# LCM32F039 register map
File version: 1.0
CPU: CM0 r1p0, little endian, MPU, no FPU, 3 interrupt priority bits
Registers are 32-bit, read-write, reset 0x0 unless marked. A register's access mark holds for its fields unless they carry their own. Offsets are from the block's base; [hi:lo] are bit positions; {n}, {i} and the like mark numbered series.

## SPI0 — ARM PrimeCell SSP (PL022)
Base 0x40018000
Same registers: SPI2 0x40006000
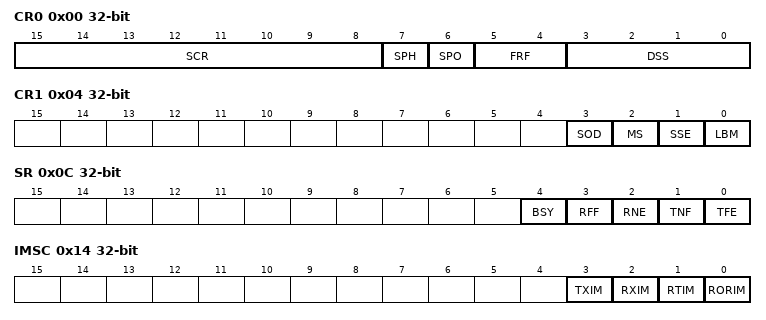
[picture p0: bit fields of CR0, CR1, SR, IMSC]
0x00 CR0 — Control register 0
  [15:8] SCR — Serial clock rate.
  [7] SPH — SSPCLKOUT phase, applicable to Motorola SPI frame format only.
  [6] SPO — SSPCLKOUT polarity, applicable to Motorola SPI frame
  [5:4] FRF — Frame format
  [3:0] DSS — Data Size Select
0x04 CR1 — Control register 1
  [3] SOD — Slave-mode output disable.
  [2] MS — Master or slave mode select
  [1] SSE — Synchronous serial port enable
  [0] LBM — Loop back mode.
0x08 DR — Data register
  [15:0] DATA — Transmit/Receive FIFO
0x0C SR ro — Status register
  [4] BSY — PrimeCell SSP busy flag
  [3] RFF — Receive FIFO full
  [2] RNE — Receive FIFO not empty
  [1] TNF — Transmit FIFO not full
  [0] TFE — Transmit FIFO empty
0x10 CPSR ro — Clock prescale register.
  [7:0] CPSDVSR — Clock prescale divisor.
0x14 IMSC — Interrupt mask set or clear register
  [3] TXIM — Transmit FIFO interrupt mask
  [2] RXIM — Receive FIFO interrupt mask
  [1] RTIM — Receive timeout interrupt mask
  [0] RORIM — Receive overrun interrupt mask
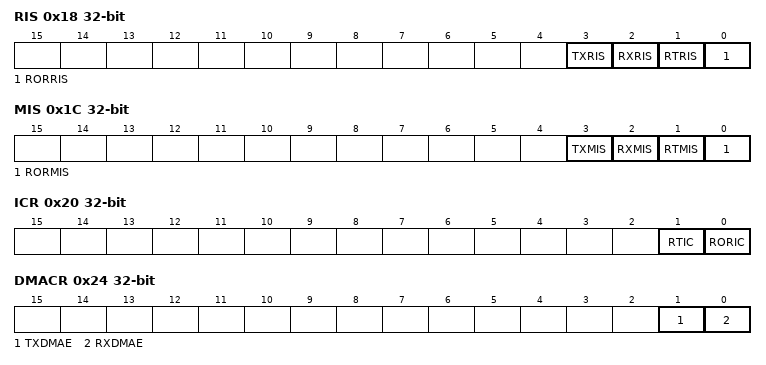
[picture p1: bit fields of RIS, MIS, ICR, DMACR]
0x18 RIS ro — Raw interrupt status register
  [3] TXRIS — Gives the raw interrupt state, prior to masking, of the SSPTXINTR interrupt
  [2] RXRIS — Gives the raw interrupt state, prior to masking, of the SSPRXINTR interrupt
  [1] RTRIS — Gives the raw interrupt state, prior to masking, of the SSPRTINTR interrupt
  [0] RORRIS — Gives the raw interrupt state, prior to masking, of the SSPRORINTR interrupt
0x1C MIS ro — Masked interrupt status register
  [3] TXMIS — Gives the transmit FIFO masked interrupt state, after masking, of the SSPTXINTR interrupt
  [2] RXMIS — Gives the receive FIFO masked interrupt state, after masking, of the SSPRXINTR interrupt
  [1] RTMIS — Gives the receive timeout masked interrupt state, after masking, of the SSPRTINTR interrupt
  [0] RORMIS — Gives the receive over run masked interrupt status, after masking, of the SSPRORINTR interrupt
0x20 ICR wo — Interrupt clear register
  [1] RTIC — Clears the SSPRTINTR interrupt
  [0] RORIC — Clears the SSPRORINTR interrupt
0x24 DMACR — DMA control register
  [1] TXDMAE — Transmit DMA Enable. If this bit is set to 1, DMA for the transmit FIFO is enabled.
  [0] RXDMAE — Receive DMA Enable. If this bit is set to 1, DMA for the receive FIFO is enabled.

## LCD — liquid crystal display
Base 0x40008000
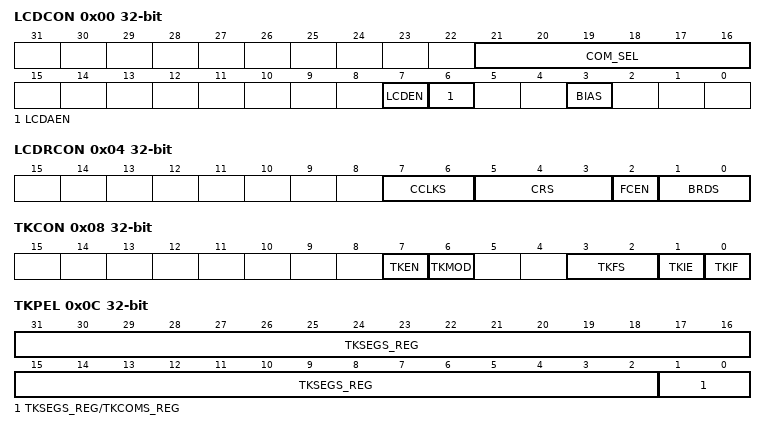
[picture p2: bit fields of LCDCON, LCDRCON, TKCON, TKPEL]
0x00 LCDCON — Flash access control register
  [21:16] COM_SEL — Enable the selection bit on the COM end
  [7] LCDEN — Enable position of the LCD module
  [6] LCDAEN — Simulation test output enable bit
  [3] BIAS — Bias level selector bit
0x04 LCDRCON — LCD resistor drive control register
  [7:6] CCLKS — Charging time selection bit
  [5:3] CRS — Contrast selector bit
  [2] FCEN — Quick charging enable.
  [1:0] BRDS — Bias resistor selection bit
0x08 TKCON — LCD flicker control register
  [7] TKEN — Blinking always enable
  [6] TKMOD — Blinking mode control bit
  [3:2] TKFS — Flicker frequency selection bit
  [1] TKIE — Blinking interrupt enable position
  [0] TKIF — Blinking interrupt flag bit
0x0C TKPEL — Blinking enable signal low level control register
  [31:2] TKSEGS_REG — Enable SEG pin
  [1:0] TKSEGS_REG/TKCOMS_REG — Com/SEG output enable bit
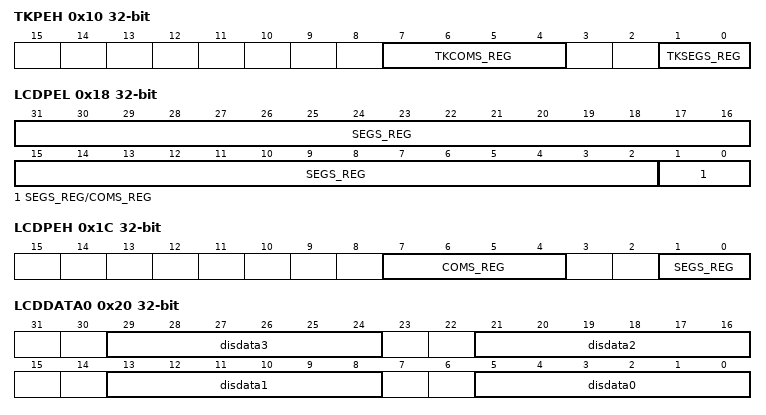
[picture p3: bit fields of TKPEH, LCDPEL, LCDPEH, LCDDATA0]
0x10 TKPEH — LCD flicker enable signal high control register
  [7:4] TKCOMS_REG — Blinking always enable
  [1:0] TKSEGS_REG — Blinking enable
0x14 LCDSCDIV — LCD scan clock source frequency division control register
  [7:0] LCDSCDIV — LCD scanning clock source frequency division control bit
0x18 LCDPEL — LCD output enable signal low level control register
  [31:2] SEGS_REG — Enable SEG pin
  [1:0] SEGS_REG/COMS_REG — Com/SEG output enable bit
0x1C LCDPEH — LCD output enable signal high control register
  [7:4] COMS_REG — Enable COM pin
  [1:0] SEGS_REG — Enable SEG pin
0x20 LCDDATA0 — SEG output data register 0
  [8n+5:8n] disdata{n} (n=0..3) — The SEG{n} pin outputs COM signals
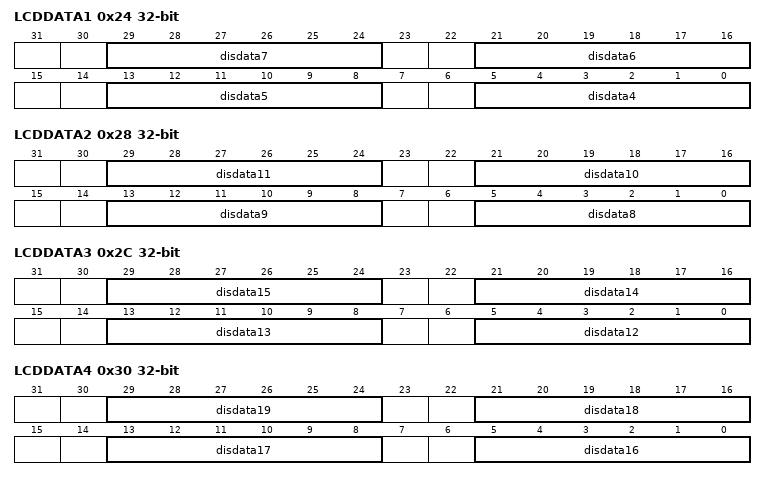
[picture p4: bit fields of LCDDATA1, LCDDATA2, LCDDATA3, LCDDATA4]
0x24 LCDDATA1 — SEG output data register 1
  [8n-27:8n-32] disdata{n} (n=4..7) — The SEG{n} pin outputs COM signals
0x28 LCDDATA2 — SEG output data register 2
  [8n-59:8n-64] disdata{n} (n=8..11) — The SEG{n} pin outputs COM signals
0x2C LCDDATA3 — SEG output data register 3
  [8n-91:8n-96] disdata{n} (n=12..15) — The SEG{n} pin outputs COM signals
0x30 LCDDATA4 — SEG output data register 4
  [8n-123:8n-128] disdata{n} (n=16..19) — The SEG{n} pin outputs COM signals
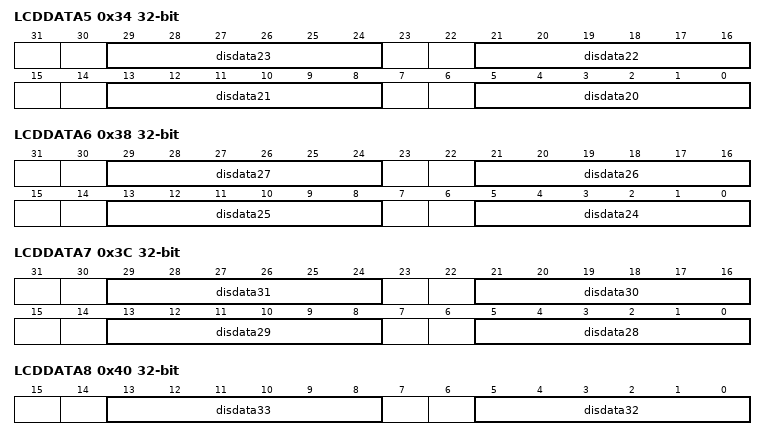
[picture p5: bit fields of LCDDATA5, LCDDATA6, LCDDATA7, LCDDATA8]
0x34 LCDDATA5 — SEG output data register 5
  [8n-155:8n-160] disdata{n} (n=20..23) — The SEG{n} pin outputs COM signals
0x38 LCDDATA6 — SEG output data register 6
  [8n-187:8n-192] disdata{n} (n=24..27) — The SEG{n} pin outputs COM signals
0x3C LCDDATA7 — SEG output data register 7
  [8n-219:8n-224] disdata{n} (n=28..31) — The SEG{n} pin outputs COM signals
0x40 LCDDATA8 — SEG output data register 8
  [13:8] disdata33 — The SEG33 pin outputs COM signals
  [5:0] disdata32 — The SEG32 pin outputs COM signals
